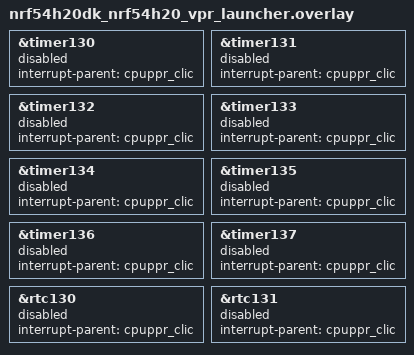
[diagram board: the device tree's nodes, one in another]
 /* SPDX-License-Identifier: Apache-2.0 */

&timer130 {
	status = "reserved";
	interrupt-parent = <&cpuppr_clic>;
};

&timer131 {
	status = "reserved";
	interrupt-parent = <&cpuppr_clic>;
};

&timer132 {
	status = "reserved";
	interrupt-parent = <&cpuppr_clic>;
};

&timer133 {
	status = "reserved";
	interrupt-parent = <&cpuppr_clic>;
};

&timer134 {
	status = "reserved";
	interrupt-parent = <&cpuppr_clic>;
};

&timer135 {
	status = "reserved";
	interrupt-parent = <&cpuppr_clic>;
};

&timer136 {
	status = "reserved";
	interrupt-parent = <&cpuppr_clic>;
};

&timer137 {
	status = "reserved";
	interrupt-parent = <&cpuppr_clic>;
};

&rtc130 {
	status = "reserved";
	interrupt-parent = <&cpuppr_clic>;
};

&rtc131 {
	status = "reserved";
	interrupt-parent = <&cpuppr_clic>;
};
